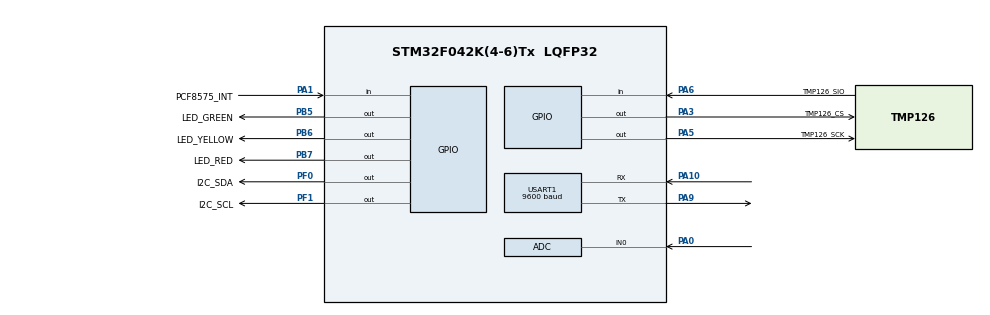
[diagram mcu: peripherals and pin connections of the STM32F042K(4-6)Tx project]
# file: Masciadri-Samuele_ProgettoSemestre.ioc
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ADC.SamplingTime=ADC_SAMPLETIME_239CYCLES_5
ADC.ScanConvMode=ADC_SCAN_DIRECTION_FORWARD
Mcu.Family=STM32F0
Mcu.Name=STM32F042K(4-6)Tx
Mcu.Package=LQFP32
NVIC.USART1_IRQn=true\:0\:0\:false\:false\:true\:true\:true\:true
PA0.Mode=IN0
PA0.Signal=ADC_IN0
PA1.GPIO_Label=PCF8575_INT
PA1.Signal=GPIO_Input
PA10.Mode=Asynchronous
PA10.Signal=USART1_RX
PA13.Mode=Serial_Wire
PA13.Signal=SYS_SWDIO
PA14.Mode=Serial_Wire
PA14.Signal=SYS_SWCLK
PA3.GPIO_Label=TMP126_CS
PA3.PinState=GPIO_PIN_SET
PA3.Signal=GPIO_Output
PA5.GPIO_Label=TMP126_SCK
PA5.Signal=GPIO_Output
PA6.GPIO_Label=TMP126_SIO
PA6.Signal=GPIO_Input
PA9.Mode=Asynchronous
PA9.Signal=USART1_TX
PB5.GPIO_Label=LED_GREEN
PB5.Signal=GPIO_Output
PB6.GPIO_Label=LED_YELLOW
PB6.Signal=GPIO_Output
PB7.GPIO_Label=LED_RED
PB7.Signal=GPIO_Output
PF0-OSC_IN.GPIO_Label=I2C_SDA
PF0-OSC_IN.GPIO_ModeDefaultOutputPP=GPIO_MODE_OUTPUT_OD
PF0-OSC_IN.GPIO_PuPd=GPIO_NOPULL
PF0-OSC_IN.PinState=GPIO_PIN_SET
PF0-OSC_IN.Signal=GPIO_Output
PF1-OSC_OUT.GPIO_Label=I2C_SCL
PF1-OSC_OUT.GPIO_ModeDefaultOutputPP=GPIO_MODE_OUTPUT_OD
PF1-OSC_OUT.GPIO_PuPd=GPIO_NOPULL
PF1-OSC_OUT.PinState=GPIO_PIN_SET
PF1-OSC_OUT.Signal=GPIO_Output
ProjectManager.HeapSize=0x200
ProjectManager.StackSize=0x400
ProjectManager.TargetToolchain=STM32CubeIDE
USART1.BaudRate=9600
USART1.VirtualMode-Asynchronous=VM_ASYNC
board=custom

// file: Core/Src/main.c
/* USER CODE BEGIN Header */
/**
  ******************************************************************************
  * @file           : main.c
  * @brief          : Main program body
  ******************************************************************************
  * @attention
  *
  * Copyright (c) 2026 STMicroelectronics.
  * All rights reserved.
  *
  * This software is licensed under terms that can be found in the LICENSE file
  * in the root directory of this software component.
  * If no LICENSE file comes with this software, it is provided AS-IS.
  *
  ******************************************************************************
  */
/* USER CODE END Header */
#include "main.h"

/* USER CODE BEGIN Includes */
#include "gpio_debug.h"
#include "uart_debug.h"
#include "tmp126.h"
#include "analog_temp.h"
#include "sw_i2c.h"
#include "pcf8575.h"
/* USER CODE END Includes */

ADC_HandleTypeDef hadc;

UART_HandleTypeDef huart1;

void SystemClock_Config(void);
static void MX_GPIO_Init(void);
static void MX_USART1_UART_Init(void);
static void MX_ADC_Init(void);

int main(void)
{

  /* MCU Configuration--------------------------------------------------------*/

  /* Reset of all peripherals, Initializes the Flash interface and the Systick. */
  HAL_Init();

  /* Configure the system clock */
  SystemClock_Config();

  /* Initialize all configured peripherals */
  MX_GPIO_Init();
  MX_USART1_UART_Init();
  MX_ADC_Init();
  /* USER CODE BEGIN 2 */
  gpio_debug_init();
  tmp126_init();
  analog_temp_init(&hadc);
  pcf8575_init(PCF8575_DEFAULT_ADDRESS);
  uart_debug_init();
  /* USER CODE END 2 */

  /* Infinite loop */
  while (1)
  {

    /* USER CODE BEGIN 3 */
    uart_debug_task();
  }
  /* USER CODE END 3 */
}

void SystemClock_Config(void)
{
  RCC_OscInitTypeDef RCC_OscInitStruct = {0};
  RCC_ClkInitTypeDef RCC_ClkInitStruct = {0};
  RCC_PeriphCLKInitTypeDef PeriphClkInit = {0};

  /** Initializes the RCC Oscillators according to the specified parameters
  * in the RCC_OscInitTypeDef structure.
  */
  RCC_OscInitStruct.OscillatorType = RCC_OSCILLATORTYPE_HSI|RCC_OSCILLATORTYPE_HSI14;
  RCC_OscInitStruct.HSIState = RCC_HSI_ON;
  RCC_OscInitStruct.HSI14State = RCC_HSI14_ON;
  RCC_OscInitStruct.HSICalibrationValue = RCC_HSICALIBRATION_DEFAULT;
  RCC_OscInitStruct.HSI14CalibrationValue = 16;
  RCC_OscInitStruct.PLL.PLLState = RCC_PLL_NONE;
  if (HAL_RCC_OscConfig(&RCC_OscInitStruct) != HAL_OK)
  {
    Error_Handler();
  }

  /** Initializes the CPU, AHB and APB buses clocks
  */
  RCC_ClkInitStruct.ClockType = RCC_CLOCKTYPE_HCLK|RCC_CLOCKTYPE_SYSCLK
                              |RCC_CLOCKTYPE_PCLK1;
  RCC_ClkInitStruct.SYSCLKSource = RCC_SYSCLKSOURCE_HSI;
  RCC_ClkInitStruct.AHBCLKDivider = RCC_SYSCLK_DIV1;
  RCC_ClkInitStruct.APB1CLKDivider = RCC_HCLK_DIV1;

  if (HAL_RCC_ClockConfig(&RCC_ClkInitStruct, FLASH_LATENCY_0) != HAL_OK)
  {
    Error_Handler();
  }
  PeriphClkInit.PeriphClockSelection = RCC_PERIPHCLK_USART1;
  PeriphClkInit.Usart1ClockSelection = RCC_USART1CLKSOURCE_PCLK1;
  if (HAL_RCCEx_PeriphCLKConfig(&PeriphClkInit) != HAL_OK)
  {
    Error_Handler();
  }
}

static void MX_ADC_Init(void)
{

  ADC_ChannelConfTypeDef sConfig = {0};

  /** Configure the global features of the ADC (Clock, Resolution, Data Alignment and number of conversion)
  */
  hadc.Instance = ADC1;
  hadc.Init.ClockPrescaler = ADC_CLOCK_ASYNC_DIV1;
  hadc.Init.Resolution = ADC_RESOLUTION_12B;
  hadc.Init.DataAlign = ADC_DATAALIGN_RIGHT;
  hadc.Init.ScanConvMode = ADC_SCAN_DIRECTION_FORWARD;
  hadc.Init.EOCSelection = ADC_EOC_SINGLE_CONV;
  hadc.Init.LowPowerAutoWait = DISABLE;
  hadc.Init.LowPowerAutoPowerOff = DISABLE;
  hadc.Init.ContinuousConvMode = DISABLE;
  hadc.Init.DiscontinuousConvMode = DISABLE;
  hadc.Init.ExternalTrigConv = ADC_SOFTWARE_START;
  hadc.Init.ExternalTrigConvEdge = ADC_EXTERNALTRIGCONVEDGE_NONE;
  hadc.Init.DMAContinuousRequests = DISABLE;
  hadc.Init.Overrun = ADC_OVR_DATA_PRESERVED;
  if (HAL_ADC_Init(&hadc) != HAL_OK)
  {
    Error_Handler();
  }

  /** Configure for the selected ADC regular channel to be converted.
  */
  sConfig.Channel = ADC_CHANNEL_0;
  sConfig.Rank = ADC_RANK_CHANNEL_NUMBER;
  sConfig.SamplingTime = ADC_SAMPLETIME_239CYCLES_5;
  if (HAL_ADC_ConfigChannel(&hadc, &sConfig) != HAL_OK)
  {
    Error_Handler();
  }

}

static void MX_USART1_UART_Init(void)
{

  huart1.Instance = USART1;
  huart1.Init.BaudRate = 9600;
  huart1.Init.WordLength = UART_WORDLENGTH_8B;
  huart1.Init.StopBits = UART_STOPBITS_1;
  huart1.Init.Parity = UART_PARITY_NONE;
  huart1.Init.Mode = UART_MODE_TX_RX;
  huart1.Init.HwFlowCtl = UART_HWCONTROL_NONE;
  huart1.Init.OverSampling = UART_OVERSAMPLING_16;
  huart1.Init.OneBitSampling = UART_ONE_BIT_SAMPLE_DISABLE;
  huart1.AdvancedInit.AdvFeatureInit = UART_ADVFEATURE_NO_INIT;
  if (HAL_UART_Init(&huart1) != HAL_OK)
  {
    Error_Handler();
  }

}

static void MX_GPIO_Init(void)
{
  GPIO_InitTypeDef GPIO_InitStruct = {0};

  /* GPIO Ports Clock Enable */
  __HAL_RCC_GPIOF_CLK_ENABLE();
  __HAL_RCC_GPIOA_CLK_ENABLE();
  __HAL_RCC_GPIOB_CLK_ENABLE();

  /*Configure GPIO pin Output Level */
  HAL_GPIO_WritePin(GPIOF, I2C_SDA_Pin|I2C_SCL_Pin, GPIO_PIN_SET);

  /*Configure GPIO pin Output Level */
  HAL_GPIO_WritePin(TMP126_CS_GPIO_Port, TMP126_CS_Pin, GPIO_PIN_SET);

  /*Configure GPIO pin Output Level */
  HAL_GPIO_WritePin(TMP126_SCK_GPIO_Port, TMP126_SCK_Pin, GPIO_PIN_RESET);

  /*Configure GPIO pin Output Level */
  HAL_GPIO_WritePin(GPIOB, LED_GREEN_Pin|LED_YELLOW_Pin|LED_RED_Pin, GPIO_PIN_RESET);

  /*Configure GPIO pins : I2C_SDA_Pin I2C_SCL_Pin */
  GPIO_InitStruct.Pin = I2C_SDA_Pin|I2C_SCL_Pin;
  GPIO_InitStruct.Mode = GPIO_MODE_OUTPUT_OD;
  GPIO_InitStruct.Pull = GPIO_NOPULL;
  GPIO_InitStruct.Speed = GPIO_SPEED_FREQ_LOW;
  HAL_GPIO_Init(GPIOF, &GPIO_InitStruct);

  /*Configure GPIO pins : PCF8575_INT_Pin TMP126_SIO_Pin */
  GPIO_InitStruct.Pin = PCF8575_INT_Pin|TMP126_SIO_Pin;
  GPIO_InitStruct.Mode = GPIO_MODE_INPUT;
  GPIO_InitStruct.Pull = GPIO_NOPULL;
  HAL_GPIO_Init(GPIOA, &GPIO_InitStruct);

  /*Configure GPIO pins : TMP126_CS_Pin TMP126_SCK_Pin */
  GPIO_InitStruct.Pin = TMP126_CS_Pin|TMP126_SCK_Pin;
  GPIO_InitStruct.Mode = GPIO_MODE_OUTPUT_PP;
  GPIO_InitStruct.Pull = GPIO_NOPULL;
  GPIO_InitStruct.Speed = GPIO_SPEED_FREQ_LOW;
  HAL_GPIO_Init(GPIOA, &GPIO_InitStruct);

  /*Configure GPIO pins : LED_GREEN_Pin LED_YELLOW_Pin LED_RED_Pin */
  GPIO_InitStruct.Pin = LED_GREEN_Pin|LED_YELLOW_Pin|LED_RED_Pin;
  GPIO_InitStruct.Mode = GPIO_MODE_OUTPUT_PP;
  GPIO_InitStruct.Pull = GPIO_NOPULL;
  GPIO_InitStruct.Speed = GPIO_SPEED_FREQ_LOW;
  HAL_GPIO_Init(GPIOB, &GPIO_InitStruct);

}

void Error_Handler(void)
{
  __disable_irq();
  while (1)
  {
  }
}
